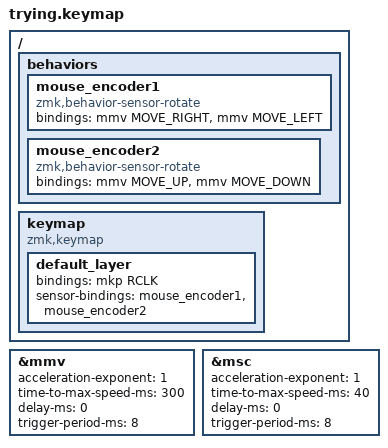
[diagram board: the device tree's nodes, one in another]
#include <behaviors.dtsi>
#include <dt-bindings/zmk/keys.h>
#include <dt-bindings/zmk/mouse.h>

&mmv {
    acceleration-exponent = <1>;      // 1
    time-to-max-speed-ms = <300>;     // 300
    delay-ms = <0>;                   // 0
    trigger-period-ms = <8>;          // 16
};

&msc {
    acceleration-exponent = <1>;      // 0
    time-to-max-speed-ms = <40>;      // 300
    delay-ms = <0>;                   // 0
    trigger-period-ms = <8>;          // 16
};

/{
 behaviors {
        mouse_encoder1: mouse_encoder1 {
            compatible = "zmk,behavior-sensor-rotate";
            #sensor-binding-cells = <0>;
            bindings = <&mmv MOVE_RIGHT>, <&mmv MOVE_LEFT>;
        };
    };
 behaviors {
        mouse_encoder2: mouse_encoder2 {
            compatible = "zmk,behavior-sensor-rotate";
            #sensor-binding-cells = <0>;
            bindings = <&mmv MOVE_UP>, <&mmv MOVE_DOWN>;
        };
    };
 keymap {
        compatible = "zmk,keymap";

        default_layer {
            bindings = <
&mkp RCLK  
            >;
        sensor-bindings = <&mouse_encoder1 &mouse_encoder2>;
        };
    };
};
